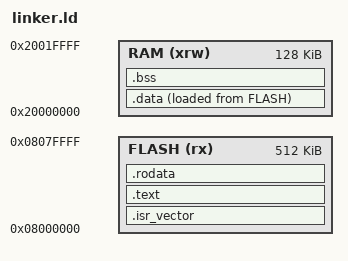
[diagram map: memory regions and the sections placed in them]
/* Minimal linker script for STM32F407 bare-metal blink. */
MEMORY
{
    FLASH (rx)  : ORIGIN = 0x08000000, LENGTH = 512K
    RAM   (xrw) : ORIGIN = 0x20000000, LENGTH = 128K
}

ENTRY(Reset_Handler)

SECTIONS
{
    .isr_vector :
    {
        . = ALIGN(4);
        KEEP(*(.isr_vector))
        . = ALIGN(4);
    } >FLASH

    .text :
    {
        . = ALIGN(4);
        *(.text*)
        . = ALIGN(4);
        _etext = .;
    } >FLASH

    .rodata :
    {
        . = ALIGN(4);
        *(.rodata*)
        . = ALIGN(4);
    } >FLASH

    .data :
    {
        . = ALIGN(4);
        _sdata = .;
        *(.data*)
        . = ALIGN(4);
        _edata = .;
    } >RAM AT> FLASH

    .bss :
    {
        . = ALIGN(4);
        _sbss = .;
        *(.bss*)
        . = ALIGN(4);
        _ebss = .;
    } >RAM
}
